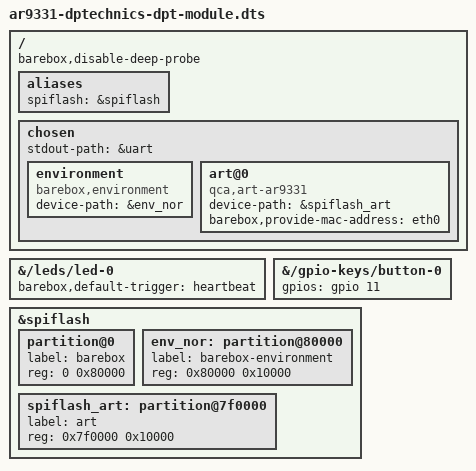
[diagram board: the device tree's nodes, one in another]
#include <mips/qca/ar9331_dpt_module.dts>
#include "ar9331.dtsi"

/ {
	barebox,disable-deep-probe;

	aliases {
		spiflash = &spiflash;
	};

	chosen {
		stdout-path = &uart;

		environment {
			compatible = "barebox,environment";
			device-path = &env_nor;
		};

		art@0 {
			compatible = "qca,art-ar9331", "qca,art";
			device-path = &spiflash_art;
			barebox,provide-mac-address = <&eth0>;
		};
	};
};

&{/leds/led-0} {
	barebox,default-trigger = "heartbeat";
};

&{/gpio-keys/button-0} {
	gpios = <&gpio 11 GPIO_ACTIVE_HIGH>;
};

&spiflash {
	partition@0 {
		label = "barebox";
		reg = <0 0x80000>;
	};

	env_nor: partition@80000 {
		label = "barebox-environment";
		reg = <0x80000 0x10000>;
	};

	spiflash_art: partition@7f0000 {
		label = "art";
		reg = <0x7f0000 0x10000>;
	};
};
